# CY8C5888LTI_LP097 register map
File version: 0.1
CY8C58LP
Registers are 8-bit, read-write, no defined reset value unless marked. A register's access mark holds for its fields unless they carry their own. Offsets are from the block's base; lines under a group give offsets from that group; [hi:lo] are bit positions; {n}, {i} and the like mark numbered series; 'fields as' and 'values as' point back to an identical list; <NAME> marks a mode.

## Memory map
0x00000000 Chip_Select_ENCODER_LINE
0x00000000 RESET_COUNTERS
0x00000000 MOTOR_ON_OFF_1
0x00000000 BLINK_25HZ
0x00000000 COUNTER_ENC
0x00000000 MY_TIMER_REG
0x00000000 BLINK_CTRL_EN
0x00000000 RESET_FF
0x00000000 FF_STATUS
0x00000000 MY_TIMER
0x00000000 UART_RS485 — UART
0x00000000 PACER_TIMER
0x00000000 PWM_MOTORS
0x00000000 BLINK_05HZ
0x00000000 LED_CTRL
0x00000000 CYCLES_TIMER

## Chip_Select_ENCODER_LINE
Base 0x00000000
0x40006579 Chip_Select_ENCODER_LINE_CONTROL_REG

## RESET_COUNTERS
Base 0x00000000
0x40006476 RESET_COUNTERS_CONTROL_REG

## MOTOR_ON_OFF_1
Base 0x00000000
0x4000657B MOTOR_ON_OFF_1_CONTROL_REG

## BLINK_25HZ
Base 0x00000000
0x40006427 BLINK_25HZ_COMPARE_Reg_ — UDB.D0 - Assigned Compare Value
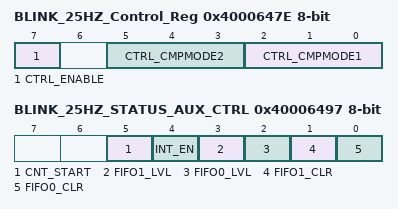
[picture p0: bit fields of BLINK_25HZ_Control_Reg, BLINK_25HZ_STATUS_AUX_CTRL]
0x4000647E BLINK_25HZ_Control_Reg — UDB Control Register - Assigned Control Register Value
  [7] CTRL_ENABLE — Enable the PWM
  [5:3] CTRL_CMPMODE2 — Compare mode 2
  [2:0] CTRL_CMPMODE1 — Compare mode 1
0x40006497 BLINK_25HZ_STATUS_AUX_CTRL — UDB Auxilliary Control Register
  [5] CNT_START — FIFO0 clear
    0=E_CNT_START0 (Disable counter); 1=E_CNT_START1 (Enable counter)
  [4] INT_EN
    0=E_INT_EN0 (Interrupt disabled); 1=E_INT_EN1 (Interrupt enabled)
  [3] FIFO1_LVL — FIFO level
    0=E_FIFO_LVL_0 (FIFO LVL: input mode: FIFO not full; output mode: FIFO not empty); 1=E_FIFO_LVL_1 (FIFO LVL: input mode: FIFO at least 1/2 empty; output mode: FIFO at least 1/2 full)
  [2] FIFO0_LVL — FIFO level
    values as FIFO1_LVL
  [1] FIFO1_CLR — FIFO1 clear
    0=E_FIFO_CLR_0 (Normal FIFO operation); 1=E_FIFO_CLR_1 (Clear FIFO state)
  [0] FIFO0_CLR — FIFO0 clear
    values as FIFO1_CLR

## COUNTER_ENC
Base 0x00000000
0x40006405 COUNTER_ENC_COUNTER — UDB.A0 - Current Counter Value
0x40006425 COUNTER_ENC_PERIOD — UDB.D0 - Assigned Period
0x40006435 COUNTER_ENC_COMPARE — UDB.D1 - Assigned Compare Value
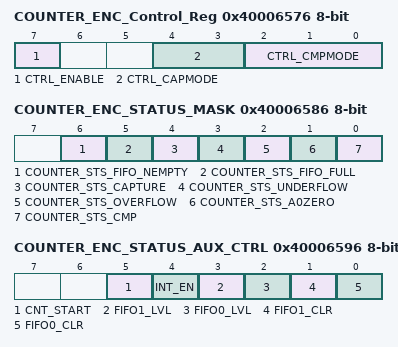
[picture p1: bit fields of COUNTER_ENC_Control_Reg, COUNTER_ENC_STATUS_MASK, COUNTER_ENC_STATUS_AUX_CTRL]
0x40006576 COUNTER_ENC_Control_Reg — UDB Control Register - Assigned Control Register Value
  [7] CTRL_ENABLE — Enable Counter
  [4:3] CTRL_CAPMODE — Capture mode
  [2:0] CTRL_CMPMODE — Compare mode
0x40006586 COUNTER_ENC_STATUS_MASK — UDB Status bits Interrupt Mask Enable Register
  [6] COUNTER_STS_FIFO_NEMPTY — FIFO Not Empty Status
  [5] COUNTER_STS_FIFO_FULL — FIFO Full Status
  [4] COUNTER_STS_CAPTURE — Capture Status
  [3] COUNTER_STS_UNDERFLOW — Underflow status
  [2] COUNTER_STS_OVERFLOW — Overflow status
  [1] COUNTER_STS_A0ZERO — A0 Zero ouput status
  [0] COUNTER_STS_CMP — Compare output status
0x40006596 COUNTER_ENC_STATUS_AUX_CTRL — UDB Auxilliary Control Register
  [5] CNT_START — FIFO0 clear
    0=E_CNT_START0 (Disable counter); 1=E_CNT_START1 (Enable counter)
  [4] INT_EN
    0=E_INT_EN0 (Interrupt disabled); 1=E_INT_EN1 (Interrupt enabled)
  [3] FIFO1_LVL — FIFO level
    0=E_FIFO_LVL_0 (FIFO LVL: input mode: FIFO not full; output mode: FIFO not empty); 1=E_FIFO_LVL_1 (FIFO LVL: input mode: FIFO at least 1/2 empty; output mode: FIFO at least 1/2 full)
  [2] FIFO0_LVL — FIFO level
    values as FIFO1_LVL
  [1] FIFO1_CLR — FIFO1 clear
    0=E_FIFO_CLR_0 (Normal FIFO operation); 1=E_FIFO_CLR_1 (Clear FIFO state)
  [0] FIFO0_CLR — FIFO0 clear
    values as FIFO1_CLR

## MY_TIMER_REG
Base 0x00000000
0x40006473 MY_TIMER_REG_CONTROL_REG

## BLINK_CTRL_EN
Base 0x00000000
0x40006478 BLINK_CTRL_EN_CONTROL_REG

## RESET_FF
Base 0x00000000
0x4000657A RESET_FF_CONTROL_REG

## FF_STATUS
Base 0x00000000
0x40006569 FF_STATUS_STATUS_REG
0x40006589 FF_STATUS_MASK_REG
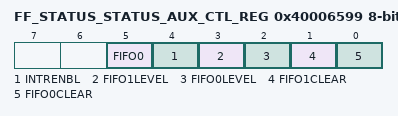
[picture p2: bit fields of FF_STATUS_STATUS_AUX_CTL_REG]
0x40006599 FF_STATUS_STATUS_AUX_CTL_REG
  [5] FIFO0 — FIFO0 clear
    1=ENABLED (Enable counter); 0=DISABLED (Disable counter)
  [4] INTRENBL — Enables or disables the Interrupt
    1=ENABLED (Interrupt enabled); 0=DISABLED (Interrupt disabled)
  [3] FIFO1LEVEL — FIFO level
    1=ENABLED (FIFO LVL: input mode: FIFO at least 1/2 empty; output mode: FIFO at least 1/2 full); 0=DISABLED (FIFO LVL: input mode: FIFO not full; output mode: FIFO not empty)
  [2] FIFO0LEVEL — FIFO level
    values as FIFO1LEVEL
  [1] FIFO1CLEAR — FIFO clear
    1=ENABLED (Clear FIFO state); 0=DISABLED (Normal FIFO operation)
  [0] FIFO0CLEAR — FIFO clear
    values as FIFO1CLEAR
